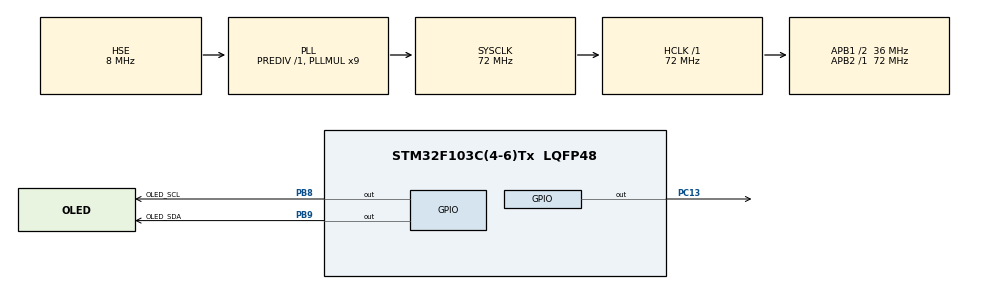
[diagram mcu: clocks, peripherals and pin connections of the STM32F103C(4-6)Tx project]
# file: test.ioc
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Mcu.Family=STM32F1
Mcu.Name=STM32F103C(4-6)Tx
Mcu.Package=LQFP48
NVIC.PriorityGroup=NVIC_PRIORITYGROUP_4
NVIC.TIM2_IRQn=true\:1\:0\:true\:false\:true\:false\:true\:true
NVIC.TimeBase=TIM2_IRQn
NVIC.TimeBaseIP=TIM2
PA13.Mode=Serial_Wire
PA13.Signal=SYS_JTMS-SWDIO
PA14.Mode=Serial_Wire
PA14.Signal=SYS_JTCK-SWCLK
PB8.GPIO_Label=OLED_SCL
PB8.GPIO_ModeDefaultOutputPP=GPIO_MODE_OUTPUT_OD
PB8.GPIO_PuPd=GPIO_PULLUP
PB8.GPIO_Speed=GPIO_SPEED_FREQ_HIGH
PB8.PinState=GPIO_PIN_SET
PB8.Signal=GPIO_Output
PB9.GPIO_Label=OLED_SDA
PB9.GPIO_ModeDefaultOutputPP=GPIO_MODE_OUTPUT_OD
PB9.GPIO_PuPd=GPIO_PULLUP
PB9.GPIO_Speed=GPIO_SPEED_FREQ_HIGH
PB9.PinState=GPIO_PIN_SET
PB9.Signal=GPIO_Output
PC13-TAMPER-RTC.PinState=GPIO_PIN_SET
PC13-TAMPER-RTC.Signal=GPIO_Output
PC14-OSC32_IN.Mode=LSE-External-Oscillator
PC14-OSC32_IN.Signal=RCC_OSC32_IN
PC15-OSC32_OUT.Mode=LSE-External-Oscillator
PC15-OSC32_OUT.Signal=RCC_OSC32_OUT
PD0-OSC_IN.Mode=HSE-External-Oscillator
PD0-OSC_IN.Signal=RCC_OSC_IN
PD1-OSC_OUT.Mode=HSE-External-Oscillator
PD1-OSC_OUT.Signal=RCC_OSC_OUT
ProjectManager.HeapSize=0x200
ProjectManager.StackSize=0x400
ProjectManager.TargetToolchain=MDK-ARM V5.32
RCC.AHBFreq_Value=72000000
RCC.APB1CLKDivider=RCC_HCLK_DIV2
RCC.APB1Freq_Value=36000000
RCC.APB1TimFreq_Value=72000000
RCC.APB2Freq_Value=72000000
RCC.APB2TimFreq_Value=72000000
RCC.HCLKFreq_Value=72000000
RCC.PLLMUL=RCC_PLL_MUL9
RCC.PLLSourceVirtual=RCC_PLLSOURCE_HSE
RCC.RTCClockSelection=RCC_RTCCLKSOURCE_LSE
RCC.SYSCLKFreq_VALUE=72000000
RCC.SYSCLKSource=RCC_SYSCLKSOURCE_PLLCLK
RCC.USBFreq_Value=72000000
RTC.Format=RTC_FORMAT_BIN
VP_RTC_No_RTC_Output.Mode=RTC_OUT_NO
VP_RTC_VS_RTC_Activate.Mode=RTC_Enabled
VP_RTC_VS_RTC_Calendar.Mode=RTC_Calendar
VP_SYS_VS_tim2.Mode=TIM2
board=custom

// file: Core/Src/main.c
/* USER CODE BEGIN Header */
/**
  ******************************************************************************
  * @file           : main.c
  * @brief          : Main program body
  ******************************************************************************
  * @attention
  *
  * Copyright (c) 2026 STMicroelectronics.
  * All rights reserved.
  *
  * This software is licensed under terms that can be found in the LICENSE file
  * in the root directory of this software component.
  * If no LICENSE file comes with this software, it is provided AS-IS.
  *
  ******************************************************************************
  */
/* USER CODE END Header */
#include "main.h"
#include "rtc.h"
#include "gpio.h"

/* USER CODE BEGIN Includes */
#include "FreeRTOS.h"
#include "task.h"
#include "startup_animation.h"
#include "oled.h"
#include "Clock.h"
/* USER CODE END Includes */

/* USER CODE BEGIN PV */
TaskHandle_t xLEDTaskHandle = NULL;
/* USER CODE END PV */

void SystemClock_Config(void);
/* USER CODE BEGIN PFP */
void vLEDTask(void *pvParameters);
/* USER CODE END PFP */

int main(void)
{

  /* MCU Configuration--------------------------------------------------------*/

  /* Reset of all peripherals, Initializes the Flash interface and the Systick. */
  HAL_Init();

  /* Configure the system clock */
  SystemClock_Config();

  /* Initialize all configured peripherals */
  MX_GPIO_Init();
  MX_RTC_Init();
  /* USER CODE BEGIN 2 */
 // 初始化OLED
    OLED_Init();
    OLED_Clear();
    // 创建开机动画任务
    if (xCreateStartupAnimationTask(2) != pdPASS)
    {
        // 创建失败处理
        OLED_ShowString(0, 0, "Anim Fail!", 8);
        OLED_Update();
    }

    // 创建LED闪烁任务
    xTaskCreate(
        vLEDTask,
        "LED",
        128,
        NULL,
        1,              // LED任务优先级1
        &xLEDTaskHandle
    );
		Clock_Task_Init();

    // 启动调度器
    vTaskStartScheduler();
  /* USER CODE END 2 */

  /* Infinite loop */
  while (1)
  {

  }
}

void SystemClock_Config(void)
{
  RCC_OscInitTypeDef RCC_OscInitStruct = {0};
  RCC_ClkInitTypeDef RCC_ClkInitStruct = {0};
  RCC_PeriphCLKInitTypeDef PeriphClkInit = {0};

  /** Initializes the RCC Oscillators according to the specified parameters
  * in the RCC_OscInitTypeDef structure.
  */
  RCC_OscInitStruct.OscillatorType = RCC_OSCILLATORTYPE_HSE|RCC_OSCILLATORTYPE_LSE;
  RCC_OscInitStruct.HSEState = RCC_HSE_ON;
  RCC_OscInitStruct.HSEPredivValue = RCC_HSE_PREDIV_DIV1;
  RCC_OscInitStruct.LSEState = RCC_LSE_ON;
  RCC_OscInitStruct.HSIState = RCC_HSI_ON;
  RCC_OscInitStruct.PLL.PLLState = RCC_PLL_ON;
  RCC_OscInitStruct.PLL.PLLSource = RCC_PLLSOURCE_HSE;
  RCC_OscInitStruct.PLL.PLLMUL = RCC_PLL_MUL9;
  if (HAL_RCC_OscConfig(&RCC_OscInitStruct) != HAL_OK)
  {
    Error_Handler();
  }

  /** Initializes the CPU, AHB and APB buses clocks
  */
  RCC_ClkInitStruct.ClockType = RCC_CLOCKTYPE_HCLK|RCC_CLOCKTYPE_SYSCLK
                              |RCC_CLOCKTYPE_PCLK1|RCC_CLOCKTYPE_PCLK2;
  RCC_ClkInitStruct.SYSCLKSource = RCC_SYSCLKSOURCE_PLLCLK;
  RCC_ClkInitStruct.AHBCLKDivider = RCC_SYSCLK_DIV1;
  RCC_ClkInitStruct.APB1CLKDivider = RCC_HCLK_DIV2;
  RCC_ClkInitStruct.APB2CLKDivider = RCC_HCLK_DIV1;

  if (HAL_RCC_ClockConfig(&RCC_ClkInitStruct, FLASH_LATENCY_2) != HAL_OK)
  {
    Error_Handler();
  }
  PeriphClkInit.PeriphClockSelection = RCC_PERIPHCLK_RTC;
  PeriphClkInit.RTCClockSelection = RCC_RTCCLKSOURCE_LSE;
  if (HAL_RCCEx_PeriphCLKConfig(&PeriphClkInit) != HAL_OK)
  {
    Error_Handler();
  }
}

/* USER CODE BEGIN 4 */
//LED闪烁任务
void vLEDTask(void *pvParameters)
{
    // 等待动画完成
    while (xAnimationCompleted == pdFALSE)
    {
        vTaskDelay(pdMS_TO_TICKS(10));
    }
    while (1)
    {
        HAL_GPIO_TogglePin(GPIOC, GPIO_PIN_13);
        vTaskDelay(pdMS_TO_TICKS(500));
    }
}

/* USER CODE END 4 */

void HAL_TIM_PeriodElapsedCallback(TIM_HandleTypeDef *htim)
{
  if (htim->Instance == TIM2)
  {
    HAL_IncTick();
  }
}

void Error_Handler(void)
{
  __disable_irq();
  while (1)
  {
  }
}
